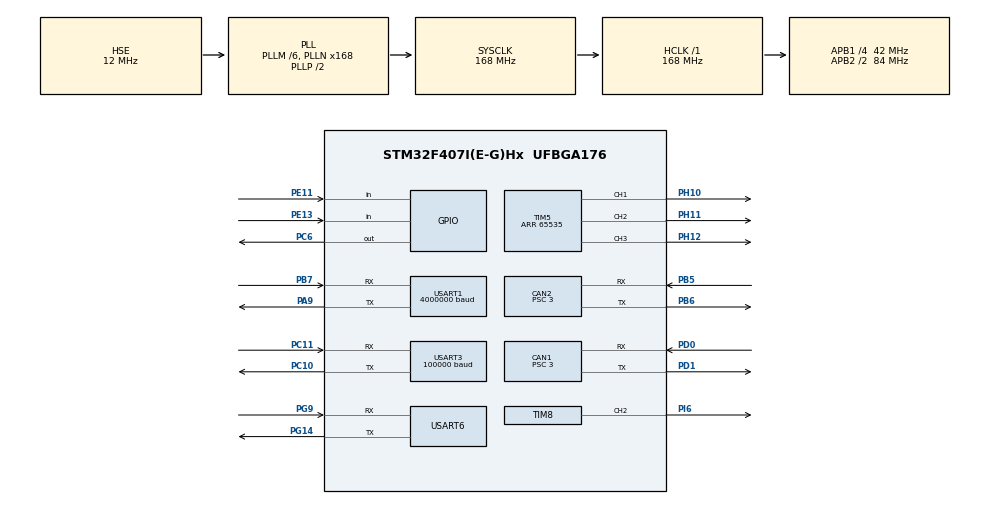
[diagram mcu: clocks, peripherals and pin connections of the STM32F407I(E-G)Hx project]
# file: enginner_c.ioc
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CAN1.ABOM=DISABLE
CAN1.BS1=CAN_BS1_10TQ
CAN1.BS2=CAN_BS2_3TQ
CAN1.CalculateBaudRate=1000000
CAN1.CalculateTimeBit=1000
CAN1.CalculateTimeQuantum=71.42857142857143
CAN1.Prescaler=3
CAN2.BS1=CAN_BS1_10TQ
CAN2.BS2=CAN_BS2_3TQ
CAN2.CalculateBaudRate=1000000
CAN2.CalculateTimeBit=1000
CAN2.CalculateTimeQuantum=71.42857142857143
CAN2.Prescaler=3
Dma.Request0=USART3_RX
Dma.Request1=TIM8_CH2
Dma.TIM8_CH2.1.Direction=DMA_MEMORY_TO_PERIPH
Dma.TIM8_CH2.1.FIFOMode=DMA_FIFOMODE_DISABLE
Dma.TIM8_CH2.1.Instance=DMA2_Stream3
Dma.TIM8_CH2.1.MemDataAlignment=DMA_MDATAALIGN_HALFWORD
Dma.TIM8_CH2.1.MemInc=DMA_MINC_ENABLE
Dma.TIM8_CH2.1.Mode=DMA_NORMAL
Dma.TIM8_CH2.1.PeriphDataAlignment=DMA_PDATAALIGN_HALFWORD
Dma.TIM8_CH2.1.PeriphInc=DMA_PINC_DISABLE
Dma.TIM8_CH2.1.Priority=DMA_PRIORITY_LOW
Dma.USART3_RX.0.Direction=DMA_PERIPH_TO_MEMORY
Dma.USART3_RX.0.FIFOMode=DMA_FIFOMODE_DISABLE
Dma.USART3_RX.0.Instance=DMA1_Stream1
Dma.USART3_RX.0.MemDataAlignment=DMA_MDATAALIGN_BYTE
Dma.USART3_RX.0.MemInc=DMA_MINC_ENABLE
Dma.USART3_RX.0.Mode=DMA_CIRCULAR
Dma.USART3_RX.0.PeriphDataAlignment=DMA_PDATAALIGN_BYTE
Dma.USART3_RX.0.PeriphInc=DMA_PINC_DISABLE
Dma.USART3_RX.0.Priority=DMA_PRIORITY_VERY_HIGH
FREERTOS.Tasks01=defaultTask,24,128,StartDefaultTask,Default,NULL,Dynamic,NULL,NULL;Kinematics,24,512,Kinematics_task,As external,NULL,Dynamic,NULL,NULL;Message,25,512,Message_task,As external,NULL,Dynamic,NULL,NULL;LED,8,128,Led_task,Default,NULL,Dynamic,NULL,NULL
Mcu.Family=STM32F4
Mcu.Name=STM32F407I(E-G)Hx
Mcu.Package=UFBGA176
NVIC.CAN1_RX0_IRQn=true\:5\:0\:false\:false\:true\:true\:true\:true\:true
NVIC.CAN2_RX0_IRQn=true\:5\:0\:false\:false\:true\:true\:true\:true\:true
NVIC.DMA1_Stream1_IRQn=true\:5\:0\:false\:false\:true\:true\:false\:true\:true
NVIC.DMA2_Stream3_IRQn=true\:5\:0\:false\:false\:true\:true\:false\:true\:true
NVIC.PriorityGroup=NVIC_PRIORITYGROUP_4
NVIC.USART1_IRQn=true\:5\:0\:false\:false\:true\:true\:true\:true\:true
NVIC.USART3_IRQn=true\:5\:0\:false\:false\:true\:true\:true\:true\:true
PA13.Mode=Serial_Wire
PA13.Signal=SYS_JTMS-SWDIO
PA14.Mode=Serial_Wire
PA14.Signal=SYS_JTCK-SWCLK
PA9.Mode=Asynchronous
PA9.Signal=USART1_TX
PB5.Mode=CAN_Activate
PB5.Signal=CAN2_RX
PB6.Mode=CAN_Activate
PB6.Signal=CAN2_TX
PB7.Mode=Asynchronous
PB7.Signal=USART1_RX
PC10.Mode=Asynchronous
PC10.Signal=USART3_TX
PC11.Mode=Asynchronous
PC11.Signal=USART3_RX
PC6.Signal=GPIO_Output
PD0.Mode=CAN_Activate
PD0.Signal=CAN1_RX
PD1.Mode=CAN_Activate
PD1.Signal=CAN1_TX
PE11.GPIO_PuPd=GPIO_PULLDOWN
PE11.Signal=GPIO_Input
PE13.GPIO_PuPd=GPIO_PULLDOWN
PE13.Signal=GPIO_Input
PG14.Mode=Asynchronous
PG14.Signal=USART6_TX
PG9.Mode=Asynchronous
PG9.Signal=USART6_RX
PH0-OSC_IN.Mode=HSE-External-Oscillator
PH0-OSC_IN.Signal=RCC_OSC_IN
PH1-OSC_OUT.Mode=HSE-External-Oscillator
PH1-OSC_OUT.Signal=RCC_OSC_OUT
PH10.Signal=S_TIM5_CH1
PH11.Signal=S_TIM5_CH2
PH12.Signal=S_TIM5_CH3
PI6.Signal=S_TIM8_CH2
ProjectManager.HeapSize=0x200
ProjectManager.StackSize=0x400
ProjectManager.TargetToolchain=MDK-ARM V5.32
RCC.48MHZClocksFreq_Value=84000000
RCC.AHBFreq_Value=168000000
RCC.APB1CLKDivider=RCC_HCLK_DIV4
RCC.APB1Freq_Value=42000000
RCC.APB1TimFreq_Value=84000000
RCC.APB2CLKDivider=RCC_HCLK_DIV2
RCC.APB2Freq_Value=84000000
RCC.APB2TimFreq_Value=168000000
RCC.CortexFreq_Value=168000000
RCC.HCLKFreq_Value=168000000
RCC.HSE_VALUE=12000000
RCC.HSI_VALUE=16000000
RCC.LSE_VALUE=32768
RCC.PLLM=6
RCC.PLLN=168
RCC.PLLSourceVirtual=RCC_PLLSOURCE_HSE
RCC.SYSCLKFreq_VALUE=168000000
RCC.SYSCLKSource=RCC_SYSCLKSOURCE_PLLCLK
RCC.VCOOutputFreq_Value=336000000
SH.S_TIM5_CH1.0=TIM5_CH1,PWM Generation1 CH1
SH.S_TIM5_CH2.0=TIM5_CH2,PWM Generation2 CH2
SH.S_TIM5_CH3.0=TIM5_CH3,PWM Generation3 CH3
SH.S_TIM8_CH2.0=TIM8_CH2,PWM Generation2 CH2
TIM5.Channel-PWM\ Generation1\ CH1=TIM_CHANNEL_1
TIM5.Channel-PWM\ Generation2\ CH2=TIM_CHANNEL_2
TIM5.Channel-PWM\ Generation3\ CH3=TIM_CHANNEL_3
TIM5.Period=65535
TIM5.Pulse-PWM\ Generation1\ CH1=10000
TIM5.Pulse-PWM\ Generation2\ CH2=10000
TIM5.Pulse-PWM\ Generation3\ CH3=10000
TIM8.Channel-PWM\ Generation2\ CH2=TIM_CHANNEL_2
TIM8.Period=209
TIM8.Prescaler=0
USART1.BaudRate=4000000
USART1.VirtualMode=VM_ASYNC
USART3.BaudRate=100000
USART3.VirtualMode=VM_ASYNC
USART6.VirtualMode=VM_ASYNC
VP_FREERTOS_VS_CMSIS_V2.Mode=CMSIS_V2
VP_TIM5_VS_ClockSourceINT.Mode=Internal
VP_TIM8_VS_ClockSourceINT.Mode=Internal
board=custom

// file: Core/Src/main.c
/* USER CODE BEGIN Header */
/**
  ******************************************************************************
  * @file           : main.c
  * @brief          : Main program body
  ******************************************************************************
  * @attention
  *
  * Copyright (c) 2023 STMicroelectronics.
  * All rights reserved.
  *
  * This software is licensed under terms that can be found in the LICENSE file
  * in the root directory of this software component.
  * If no LICENSE file comes with this software, it is provided AS-IS.
  *
  ******************************************************************************
  */
/* USER CODE END Header */
#include "main.h"
#include "cmsis_os.h"
#include "can.h"
#include "dma.h"
#include "tim.h"
#include "usart.h"
#include "gpio.h"

/* USER CODE BEGIN Includes */
#include "remote_control.h"
#include "RGB.h"
/* USER CODE END Includes */

void SystemClock_Config(void);
void MX_FREERTOS_Init(void);

int main(void)
{

  /* MCU Configuration--------------------------------------------------------*/

  /* Reset of all peripherals, Initializes the Flash interface and the Systick. */
  HAL_Init();

  /* Configure the system clock */
  SystemClock_Config();

  /* Initialize all configured peripherals */
  MX_GPIO_Init();
  MX_DMA_Init();
  MX_USART3_UART_Init();
  MX_USART1_UART_Init();
  MX_USART6_UART_Init();
  MX_CAN1_Init();
  MX_CAN2_Init();
  MX_TIM5_Init();
  MX_TIM8_Init();
  /* USER CODE BEGIN 2 */
	can_filter_init();
  remote_control_init();
	HAL_TIM_Base_Start(&htim5);
	HAL_TIM_PWM_Start(&htim5, TIM_CHANNEL_1);
  HAL_TIM_PWM_Start(&htim5, TIM_CHANNEL_2);
  HAL_TIM_PWM_Start(&htim5, TIM_CHANNEL_3);
  /* USER CODE END 2 */

  /* Init scheduler */
  osKernelInitialize();  /* Call init function for freertos objects (in freertos.c) */
  MX_FREERTOS_Init();

  /* Start scheduler */
  osKernelStart();

  /* We should never get here as control is now taken by the scheduler */
  /* Infinite loop */
  while (1)
  {

  }
}

void SystemClock_Config(void)
{
  RCC_OscInitTypeDef RCC_OscInitStruct = {0};
  RCC_ClkInitTypeDef RCC_ClkInitStruct = {0};

  /** Configure the main internal regulator output voltage
  */
  __HAL_RCC_PWR_CLK_ENABLE();
  __HAL_PWR_VOLTAGESCALING_CONFIG(PWR_REGULATOR_VOLTAGE_SCALE1);

  /** Initializes the RCC Oscillators according to the specified parameters
  * in the RCC_OscInitTypeDef structure.
  */
  RCC_OscInitStruct.OscillatorType = RCC_OSCILLATORTYPE_HSE;
  RCC_OscInitStruct.HSEState = RCC_HSE_ON;
  RCC_OscInitStruct.PLL.PLLState = RCC_PLL_ON;
  RCC_OscInitStruct.PLL.PLLSource = RCC_PLLSOURCE_HSE;
  RCC_OscInitStruct.PLL.PLLM = 6;
  RCC_OscInitStruct.PLL.PLLN = 168;
  RCC_OscInitStruct.PLL.PLLP = RCC_PLLP_DIV2;
  RCC_OscInitStruct.PLL.PLLQ = 4;
  if (HAL_RCC_OscConfig(&RCC_OscInitStruct) != HAL_OK)
  {
    Error_Handler();
  }

  /** Initializes the CPU, AHB and APB buses clocks
  */
  RCC_ClkInitStruct.ClockType = RCC_CLOCKTYPE_HCLK|RCC_CLOCKTYPE_SYSCLK
                              |RCC_CLOCKTYPE_PCLK1|RCC_CLOCKTYPE_PCLK2;
  RCC_ClkInitStruct.SYSCLKSource = RCC_SYSCLKSOURCE_PLLCLK;
  RCC_ClkInitStruct.AHBCLKDivider = RCC_SYSCLK_DIV1;
  RCC_ClkInitStruct.APB1CLKDivider = RCC_HCLK_DIV4;
  RCC_ClkInitStruct.APB2CLKDivider = RCC_HCLK_DIV2;

  if (HAL_RCC_ClockConfig(&RCC_ClkInitStruct, FLASH_LATENCY_5) != HAL_OK)
  {
    Error_Handler();
  }
}

void Error_Handler(void)
{
  __disable_irq();
  while (1)
  {
  }
}
